# HDSC_HC32F46X register map
Vendor: HDSC Co.,Ltd.; Series: ARMCM4; File version: 1.0
CPU: CM4 r0p1, little endian, MPU, FPU, 4 interrupt priority bits
Registers are 32-bit, read-write, reset 0x0 unless marked. A register's access mark holds for its fields unless they carry their own. Offsets are from the block's base; [hi:lo] are bit positions; {n}, {i} and the like mark numbered series.

## CRC
Base 0x40008800
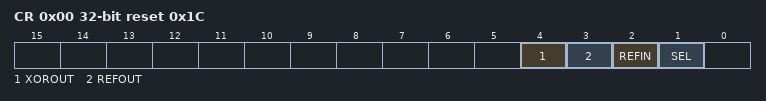
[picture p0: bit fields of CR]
0x00 CR reset 0x1C
  [4] XOROUT, [3] REFOUT, [2] REFIN, [1] SEL
0x04 RESLT reset 0x7800
0x0C FLG ro reset 0x1
  [0] FLAG
{0x80+4i} DAT{i} ro (i=0..31)

## DBGC
Base 0xE0042000
{0x0+4i} AUTHID{i} (i=0..2)
0x0C RESV0
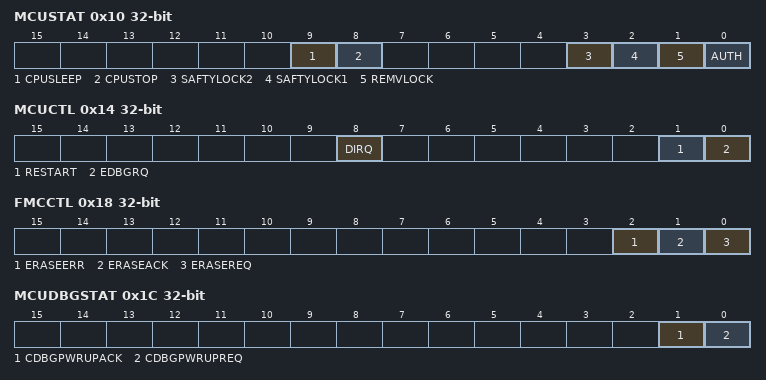
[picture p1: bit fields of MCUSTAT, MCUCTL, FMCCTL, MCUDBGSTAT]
0x10 MCUSTAT
  [9] CPUSLEEP, [8] CPUSTOP, [3] SAFTYLOCK2, [2] SAFTYLOCK1, [1] REMVLOCK, [0] AUTH
0x14 MCUCTL
  [8] DIRQ, [1] RESTART, [0] EDBGRQ
0x18 FMCCTL
  [2] ERASEERR, [1] ERASEACK, [0] ERASEREQ
0x1C MCUDBGSTAT
  [1] CDBGPWRUPACK, [0] CDBGPWRUPREQ
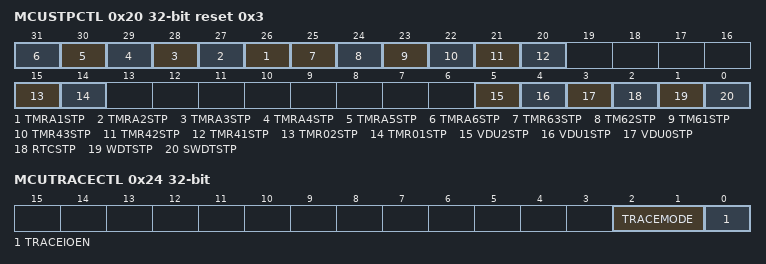
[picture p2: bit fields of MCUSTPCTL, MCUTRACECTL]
0x20 MCUSTPCTL reset 0x3
  [n+25] TMRA{n}STP (n=1..6), [25] TMR63STP, [24] TM62STP, [23] TM61STP, [22] TMR43STP, [21] TMR42STP, [20] TMR41STP, [15] TMR02STP, [14] TMR01STP, [5] VDU2STP, [4] VDU1STP, [3] VDU0STP, [2] RTCSTP, [1] WDTSTP, [0] SWDTSTP
0x24 MCUTRACECTL
  [2:1] TRACEMODE, [0] TRACEIOEN

## DCU1 — desc DCU
Base 0x40052000
Same registers: DCU2 0x40052400, DCU3 0x40052800, DCU4 0x40052C00
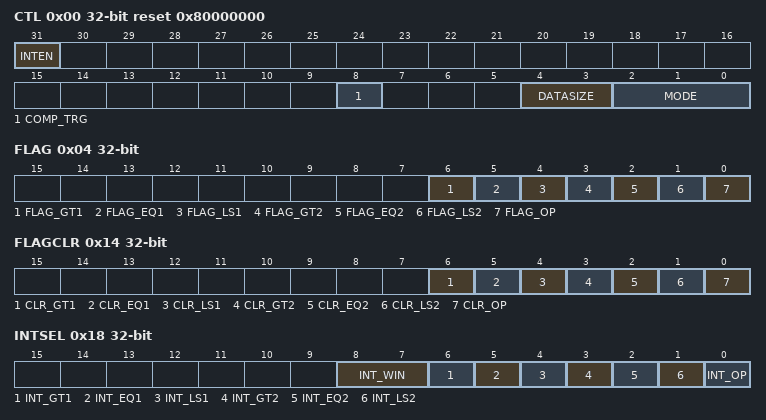
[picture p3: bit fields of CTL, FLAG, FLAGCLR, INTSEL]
0x00 CTL reset 0x80000000
  [31] INTEN, [8] COMP_TRG, [4:3] DATASIZE, [2:0] MODE
0x04 FLAG ro
  [6] FLAG_GT1, [5] FLAG_EQ1, [4] FLAG_LS1, [3] FLAG_GT2, [2] FLAG_EQ2, [1] FLAG_LS2, [0] FLAG_OP
{0x8+4i} DATA{i} (i=0..2)
0x14 FLAGCLR wo
  [6] CLR_GT1, [5] CLR_EQ1, [4] CLR_LS1, [3] CLR_GT2, [2] CLR_EQ2, [1] CLR_LS2, [0] CLR_OP
0x18 INTSEL
  [8:7] INT_WIN, [6] INT_GT1, [5] INT_EQ1, [4] INT_LS1, [3] INT_GT2, [2] INT_EQ2, [1] INT_LS2, [0] INT_OP

## DMA1 — desc DMA
Base 0x40053000
Same registers: DMA2 0x40053400
0x00 EN
  [0] EN
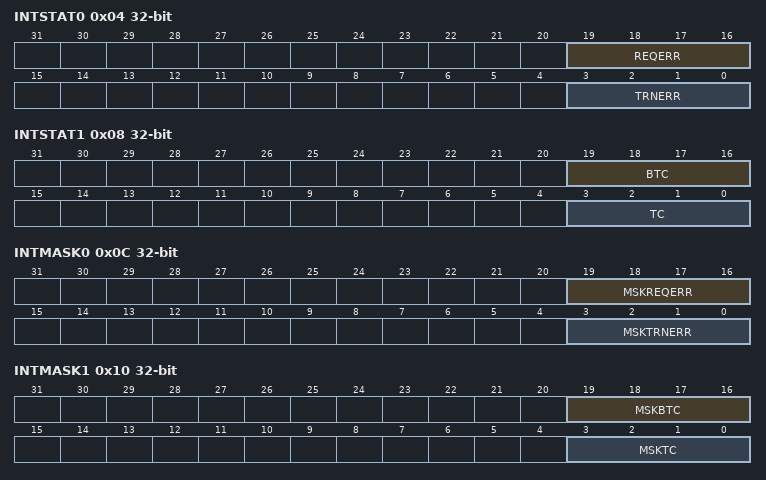
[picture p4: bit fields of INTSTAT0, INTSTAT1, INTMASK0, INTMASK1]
0x04 INTSTAT0 ro
  [19:16] REQERR, [3:0] TRNERR
0x08 INTSTAT1 ro
  [19:16] BTC, [3:0] TC
0x0C INTMASK0
  [19:16] MSKREQERR, [3:0] MSKTRNERR
0x10 INTMASK1
  [19:16] MSKBTC, [3:0] MSKTC
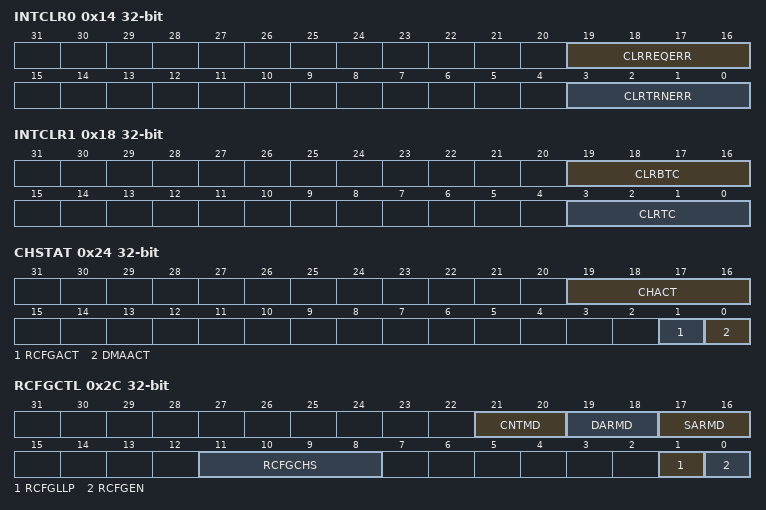
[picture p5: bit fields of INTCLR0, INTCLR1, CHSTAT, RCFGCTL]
0x14 INTCLR0 wo
  [19:16] CLRREQERR, [3:0] CLRTRNERR
0x18 INTCLR1 wo
  [19:16] CLRBTC, [3:0] CLRTC
0x1C CHEN
  [3:0] CHEN
0x24 CHSTAT ro
  [19:16] CHACT, [1] RCFGACT, [0] DMAACT
0x2C RCFGCTL
  [21:20] CNTMD, [19:18] DARMD, [17:16] SARMD, [11:8] RCFGCHS, [1] RCFGLLP, [0] RCFGEN
{0x40+0x40*i} SAR{i} (i=0..3)
{0x44+0x40*i} DAR{i} (i=0..3)
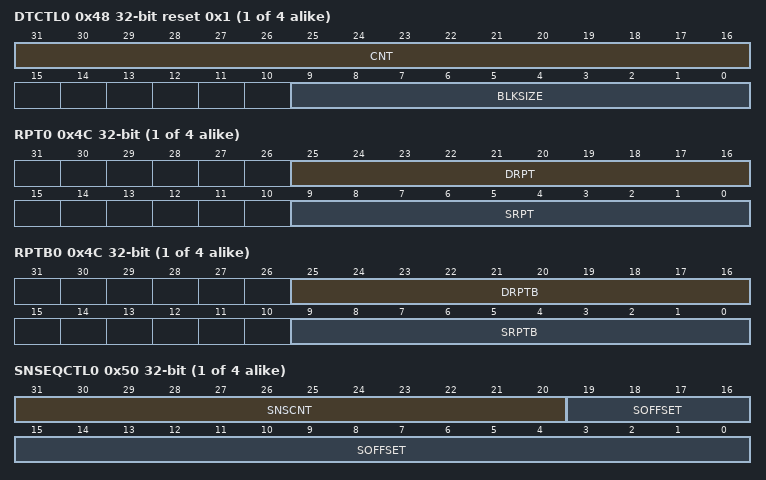
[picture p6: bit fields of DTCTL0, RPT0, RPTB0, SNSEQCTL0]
{0x48+0x40*i} DTCTL{i} reset 0x1 (i=0..3)
  [31:16] CNT, [9:0] BLKSIZE
{0x4C+0x40*i} RPT{i} (i=0..3)
  [25:16] DRPT, [9:0] SRPT
{0x4C+0x40*i} RPTB{i} (i=0..3)
  [25:16] DRPTB, [9:0] SRPTB
{0x50+0x40*i} SNSEQCTL{i} (i=0..3)
  [31:20] SNSCNT, [19:0] SOFFSET
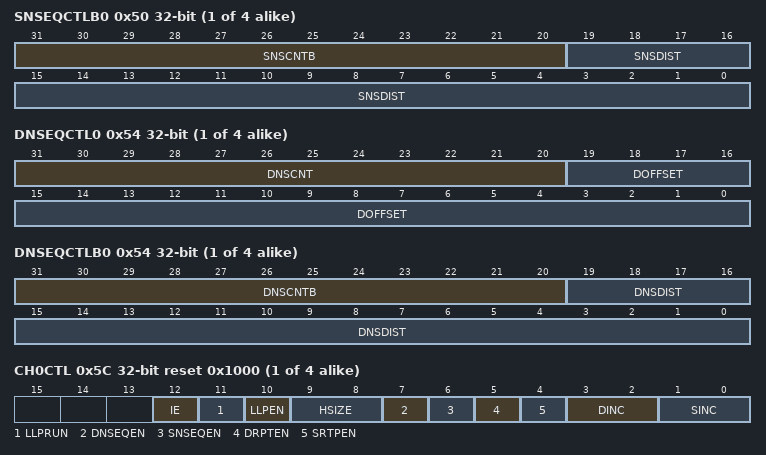
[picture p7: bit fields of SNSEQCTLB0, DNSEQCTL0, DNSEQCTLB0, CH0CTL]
{0x50+0x40*i} SNSEQCTLB{i} (i=0..3)
  [31:20] SNSCNTB, [19:0] SNSDIST
{0x54+0x40*i} DNSEQCTL{i} (i=0..3)
  [31:20] DNSCNT, [19:0] DOFFSET
{0x54+0x40*i} DNSEQCTLB{i} (i=0..3)
  [31:20] DNSCNTB, [19:0] DNSDIST
{0x58+0x40*i} LLP{i} (i=0..3)
  [31:2] LLP
{0x5C+0x40*i} CH{i}CTL reset 0x1000 (i=0..3)
  [12] IE, [11] LLPRUN, [10] LLPEN, [9:8] HSIZE, [7] DNSEQEN, [6] SNSEQEN, [5] DRPTEN, [4] SRTPEN, [3:2] DINC, [1:0] SINC

## EFM
Base 0x40010400
0x00 FAPRT
  [15:0] FAPRT
0x04 FSTP
  [0] FSTP
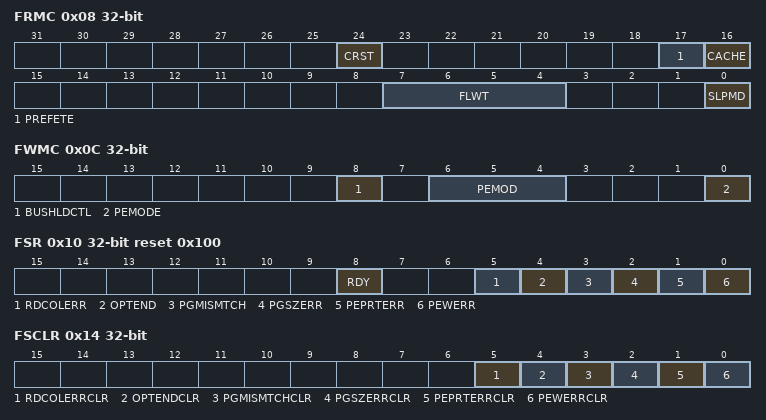
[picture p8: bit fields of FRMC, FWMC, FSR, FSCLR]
0x08 FRMC
  [24] CRST, [17] PREFETE, [16] CACHE, [7:4] FLWT, [0] SLPMD
0x0C FWMC
  [8] BUSHLDCTL, [6:4] PEMOD, [0] PEMODE
0x10 FSR ro reset 0x100
  [8] RDY, [5] RDCOLERR, [4] OPTEND, [3] PGMISMTCH, [2] PGSZERR, [1] PEPRTERR, [0] PEWERR
0x14 FSCLR
  [5] RDCOLERRCLR, [4] OPTENDCLR, [3] PGMISMTCHCLR, [2] PGSZERRCLR, [1] PEPRTERRCLR, [0] PEWERRCLR
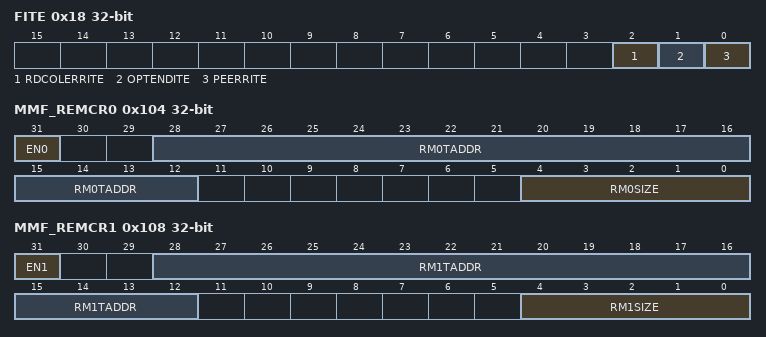
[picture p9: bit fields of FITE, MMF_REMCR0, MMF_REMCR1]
0x18 FITE
  [2] RDCOLERRITE, [1] OPTENDITE, [0] PEERRITE
0x1C FSWP ro reset 0x1
  [0] FSWP
0x20 FPMTSW
  [19:0] FPMTSW
0x24 FPMTEW
  [19:0] FPMTEW
{0x4C+4i} UQID{i} ro (i=1..3)
0x100 MMF_REMPRT
  [15:0] REMPRT
0x104 MMF_REMCR0
  [31] EN0, [28:12] RM0TADDR, [4:0] RM0SIZE
0x108 MMF_REMCR1
  [31] EN1, [28:12] RM1TADDR, [4:0] RM1SIZE

## EMB1 — desc EMB
Base 0x40017C00
Same registers: EMB2 0x40017C20, EMB3 0x40017C40, EMB4 0x40017C60
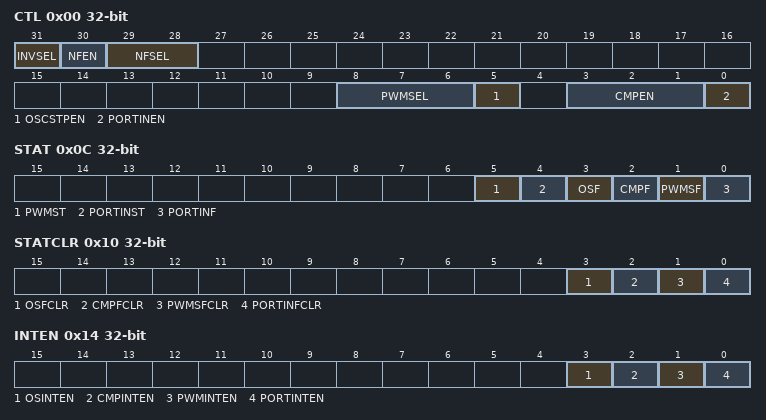
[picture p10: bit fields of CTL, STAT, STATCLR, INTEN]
0x00 CTL
  [31] INVSEL, [30] NFEN, [29:28] NFSEL, [8:6] PWMSEL, [5] OSCSTPEN, [3:1] CMPEN, [0] PORTINEN
0x04 PWMLV
  [2:0] PWMLV
0x08 SOE
  [0] SOE
0x0C STAT ro
  [5] PWMST, [4] PORTINST, [3] OSF, [2] CMPF, [1] PWMSF, [0] PORTINF
0x10 STATCLR wo
  [3] OSFCLR, [2] CMPFCLR, [1] PWMSFCLR, [0] PORTINFCLR
0x14 INTEN
  [3] OSINTEN, [2] CMPINTEN, [1] PWMINTEN, [0] PORTINTEN
